# CY8C3246PVI_147 register map
File version: 0.1
Registers are 8-bit, read-write, no defined reset value unless marked. A register's access mark holds for its fields unless they carry their own. Offsets are from the block's base; [hi:lo] are bit positions; {n}, {i} and the like mark numbered series; 'fields as' and 'values as' point back to an identical list.

## I2S
Base 0x00000000
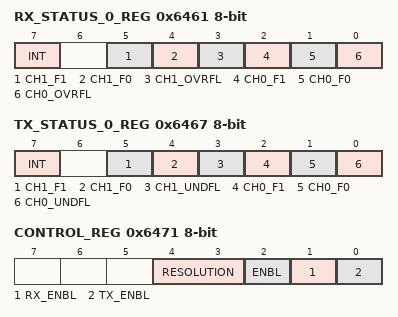
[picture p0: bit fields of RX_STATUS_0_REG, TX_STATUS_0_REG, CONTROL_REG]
0x6461 RX_STATUS_0_REG
  [7] INT ro — Interrupt bit
  [5] CH1_F1 ro — Stereo channel 1 FIFO 1 state
    0=EMPTY; 1=NOT_EMPTY
  [4] CH1_F0 ro — Stereo channel 1 FIFO 0 state
    0=EMPTY; 1=NOT_EMPTY
  [3] CH1_OVRFL ro — Stereo channel 1 FIFO overflow
    0=NO_OVERFLOW; 1=OVERFLOW
  [2] CH0_F1 ro — Stereo channel 0 FIFO 1 state
    0=EMPTY; 1=NOT_EMPTY
  [1] CH0_F0 ro — Stereo channel 0 FIFO 0 state
    0=EMPTY; 1=NOT_EMPTY
  [0] CH0_OVRFL ro — Stereo channel 0 FIFO overflow
    0=NO_OVERFLOW; 1=OVERFLOW
0x6467 TX_STATUS_0_REG
  [7] INT ro — Interrupt bit
  [5] CH1_F1 ro — Stereo channel 1 FIFO 1 state
    0=FULL; 1=NOT_FULL
  [4] CH1_F0 ro — Stereo channel 1 FIFO 0 state
    0=FULL; 1=NOT_FULL
  [3] CH1_UNDFL ro — Stereo channel 1 FIFO underflow
    0=NO_UNDERFLOW; 1=UNDERFLOW
  [2] CH0_F1 ro — Stereo channel 0 FIFO 1 state
    0=FULL; 1=NOT_FULL
  [1] CH0_F0 ro — Stereo channel 0 FIFO 0 state
    0=FULL; 1=NOT_FULL
  [0] CH0_UNDFL ro — Stereo channel 0 FIFO underflow
    0=NO_UNDERFLOW; 1=UNDERFLOW
0x6471 CONTROL_REG
  [4:3] RESOLUTION — Specifies data bits value. Applicable only if dynamic bit resolution is selected.
    0=8_BIT; 1=16_BIT; 2=24_BIT; 3=32_BIT
  [2] ENBL — Starts the generation of the WS and SCK outputs.
    1=ENABLED; 0=DISABLED
  [1] RX_ENBL — Enables Rx direction. Applicable only if Rx direction presents for the component.
    1=ENABLED; 0=DISABLED
  [0] TX_ENBL — Enables Tx direction. Applicable only if Tx direction presents for the component.
    1=ENABLED; 0=DISABLED

## USBFS
Base 0x00000000
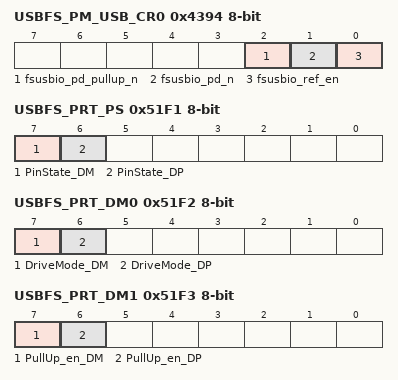
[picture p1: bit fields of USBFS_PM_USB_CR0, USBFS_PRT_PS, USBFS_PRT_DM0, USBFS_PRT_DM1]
0x4394 USBFS_PM_USB_CR0 — USB Power Mode Control Register 0
  [2] fsusbio_pd_pullup_n, [1] fsusbio_pd_n, [0] fsusbio_ref_en
0x43A5 USBFS_PM_ACT_CFG — Active Power Mode Configuration Register
0x43B5 USBFS_PM_STBY_CFG — Standby Power Mode Configuration Register
0x51F1 USBFS_PRT_PS — Port Pin State Register
  [7] PinState_DM ro, [6] PinState_DP ro
0x51F2 USBFS_PRT_DM0 — Port Drive Mode Register
  [7] DriveMode_DM, [6] DriveMode_DP
0x51F3 USBFS_PRT_DM1 — Port Drive Mode Register
  [7] PullUp_en_DM, [6] PullUp_en_DP
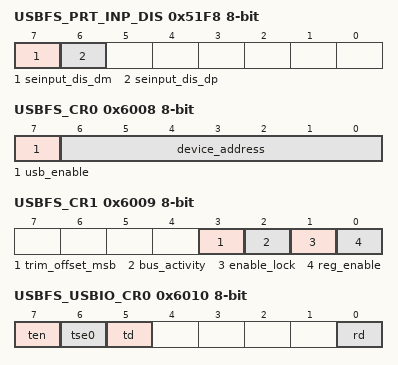
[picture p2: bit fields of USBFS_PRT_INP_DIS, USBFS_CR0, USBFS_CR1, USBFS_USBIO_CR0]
0x51F8 USBFS_PRT_INP_DIS — Input buffer disable override
  [7] seinput_dis_dm, [6] seinput_dis_dp
0x6000 USBFS_EP0_DR0 — bmRequestType
0x6001 USBFS_EP0_DR1 — bRequest
0x6002 USBFS_EP0_DR2 — wValueLo
0x6003 USBFS_EP0_DR3 — wValueHi
0x6004 USBFS_EP0_DR4 — wIndexLo
0x6005 USBFS_EP0_DR5 — wIndexHi
0x6006 USBFS_EP0_DR6 — lengthLo
0x6007 USBFS_EP0_DR7 — lengthHi
0x6008 USBFS_CR0 — USB Control Register 0
  [7] usb_enable, [6:0] device_address ro
0x6009 USBFS_CR1 — USB Control Register 1
  [3] trim_offset_msb, [2] bus_activity, [1] enable_lock, [0] reg_enable
{0x5FFE+0x10*i} USBFS_SIE_EP{i}_CR0 (i=1..8) — The Endpoint{i} Control Register
0x6010 USBFS_USBIO_CR0 — USBIO Control Register 0
  [7] ten, [6] tse0, [5] td, [0] rd ro
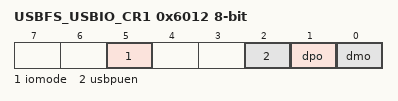
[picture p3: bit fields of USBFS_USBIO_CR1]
0x6012 USBFS_USBIO_CR1 — USBIO Control Register 1
  [5] iomode, [2] usbpuen, [1] dpo ro, [0] dmo ro
0x608C USBFS_BUF_SIZE — Dedicated Endpoint Buffer Size Register
0x608E USBFS_EP_ACTIVE — Endpoint Active Indication Register
0x608F USBFS_EP_TYPE — Endpoint Type (IN/OUT) Indication
0x609D USBFS_USB_CLK_EN — USB Block Clock Enable Register

## USBFS_EP8_DMA_Done_SR
Base 0x0000646B
0x00 USBFS_EP8_DMA_Done_SR_STATUS_REG
0x20 USBFS_EP8_DMA_Done_SR_MASK_REG
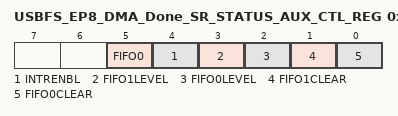
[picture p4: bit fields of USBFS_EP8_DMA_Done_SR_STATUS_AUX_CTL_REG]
0x30 USBFS_EP8_DMA_Done_SR_STATUS_AUX_CTL_REG
  [5] FIFO0 — FIFO0 clear
    1=ENABLED (Enable counter); 0=DISABLED (Disable counter)
  [4] INTRENBL — Enables or disables the Interrupt
    1=ENABLED (Interrupt enabled); 0=DISABLED (Interrupt disabled)
  [3] FIFO1LEVEL — FIFO level
    1=ENABLED (FIFO LVL: input mode: FIFO at least 1/2 empty; output mode: FIFO at least 1/2 full); 0=DISABLED (FIFO LVL: input mode: FIFO not full; output mode: FIFO not empty)
  [2] FIFO0LEVEL — FIFO level
    values as FIFO1LEVEL
  [1] FIFO1CLEAR — FIFO clear
    1=ENABLED (Clear FIFO state); 0=DISABLED (Normal FIFO operation)
  [0] FIFO0CLEAR — FIFO clear
    values as FIFO1CLEAR

## USBFS_EP17_DMA_Done_SR
Base 0x0000646C
Registers as USBFS_EP8_DMA_Done_SR (with USBFS_EP8_DMA_Done_SR read as USBFS_EP17_DMA_Done_SR).

## Status
Base 0x0000646A
Registers as USBFS_EP8_DMA_Done_SR (with USBFS_EP8_DMA_Done_SR read as Status).
